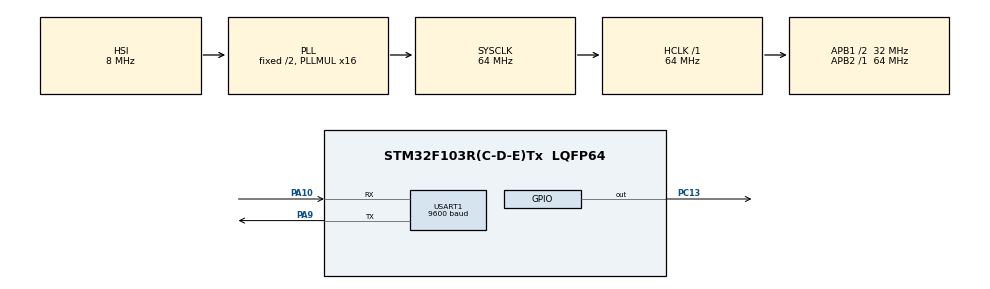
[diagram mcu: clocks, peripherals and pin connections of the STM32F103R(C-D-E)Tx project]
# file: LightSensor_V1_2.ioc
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Dma.Request0=USART1_RX
Dma.Request1=USART1_TX
Dma.USART1_RX.0.Direction=DMA_PERIPH_TO_MEMORY
Dma.USART1_RX.0.Instance=DMA1_Channel5
Dma.USART1_RX.0.MemDataAlignment=DMA_MDATAALIGN_BYTE
Dma.USART1_RX.0.MemInc=DMA_MINC_ENABLE
Dma.USART1_RX.0.Mode=DMA_NORMAL
Dma.USART1_RX.0.PeriphDataAlignment=DMA_PDATAALIGN_BYTE
Dma.USART1_RX.0.PeriphInc=DMA_PINC_DISABLE
Dma.USART1_RX.0.Priority=DMA_PRIORITY_LOW
Dma.USART1_TX.1.Direction=DMA_MEMORY_TO_PERIPH
Dma.USART1_TX.1.Instance=DMA1_Channel4
Dma.USART1_TX.1.MemDataAlignment=DMA_MDATAALIGN_BYTE
Dma.USART1_TX.1.MemInc=DMA_MINC_ENABLE
Dma.USART1_TX.1.Mode=DMA_NORMAL
Dma.USART1_TX.1.PeriphDataAlignment=DMA_PDATAALIGN_BYTE
Dma.USART1_TX.1.PeriphInc=DMA_PINC_DISABLE
Dma.USART1_TX.1.Priority=DMA_PRIORITY_LOW
FREERTOS.Tasks01=defaultTask,24,128,StartDefaultTask,Default,NULL,Dynamic,NULL,NULL
IWDG.Reload=3000
Mcu.Family=STM32F1
Mcu.Name=STM32F103R(C-D-E)Tx
Mcu.Package=LQFP64
NVIC.DMA1_Channel4_IRQn=true\:5\:0\:false\:false\:true\:true\:false\:true\:true
NVIC.DMA1_Channel5_IRQn=true\:5\:0\:false\:false\:true\:true\:false\:true\:true
NVIC.PriorityGroup=NVIC_PRIORITYGROUP_4
NVIC.TIM1_UP_IRQn=true\:15\:0\:false\:false\:true\:false\:false\:true\:true
NVIC.TimeBase=TIM1_UP_IRQn
NVIC.TimeBaseIP=TIM1
NVIC.USART1_IRQn=true\:5\:0\:false\:false\:true\:true\:true\:true\:true
PA10.Mode=Asynchronous
PA10.Signal=USART1_RX
PA13.Mode=Serial_Wire
PA13.Signal=SYS_JTMS-SWDIO
PA14.Mode=Serial_Wire
PA14.Signal=SYS_JTCK-SWCLK
PA9.Mode=Asynchronous
PA9.Signal=USART1_TX
PC13-TAMPER-RTC.GPIO_PuPd=GPIO_PULLUP
PC13-TAMPER-RTC.PinState=GPIO_PIN_SET
PC13-TAMPER-RTC.Signal=GPIO_Output
PC14-OSC32_IN.Mode=LSE-External-Oscillator
PC14-OSC32_IN.Signal=RCC_OSC32_IN
PC15-OSC32_OUT.Mode=LSE-External-Oscillator
PC15-OSC32_OUT.Signal=RCC_OSC32_OUT
ProjectManager.HeapSize=0x200
ProjectManager.StackSize=0x400
ProjectManager.TargetToolchain=MDK-ARM V5.32
RCC.AHBFreq_Value=64000000
RCC.APB1CLKDivider=RCC_HCLK_DIV2
RCC.APB1Freq_Value=32000000
RCC.APB1TimFreq_Value=64000000
RCC.APB2Freq_Value=64000000
RCC.APB2TimFreq_Value=64000000
RCC.HCLKFreq_Value=64000000
RCC.PLLMUL=RCC_PLL_MUL16
RCC.SYSCLKFreq_VALUE=64000000
RCC.SYSCLKSource=RCC_SYSCLKSOURCE_PLLCLK
RCC.USBFreq_Value=64000000
USART1.BaudRate=9600
USART1.VirtualMode=VM_ASYNC
VP_FREERTOS_VS_CMSIS_V2.Mode=CMSIS_V2
VP_IWDG_VS_IWDG.Mode=IWDG_Activate
VP_RTC_VS_RTC_Activate.Mode=RTC_Enabled
VP_RTC_VS_RTC_Calendar.Mode=RTC_Calendar
VP_SYS_VS_tim1.Mode=TIM1
board=custom

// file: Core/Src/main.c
/* USER CODE BEGIN Header */
/**
  ******************************************************************************
  * @file           : main.c
  * @brief          : Main program body
  ******************************************************************************
  * @attention
  *
  * Copyright (c) 2023 STMicroelectronics.
  * All rights reserved.
  *
  * This software is licensed under terms that can be found in the LICENSE file
  * in the root directory of this software component.
  * If no LICENSE file comes with this software, it is provided AS-IS.
  *
  ******************************************************************************
  */
/* USER CODE END Header */
#include "main.h"
#include "cmsis_os.h"
#include "dma.h"
#include "iwdg.h"
#include "rtc.h"
#include "usart.h"
#include "gpio.h"

/* USER CODE BEGIN Includes */
#include "stm32f1xx_it.h"
#include "user_TasksInit.h"
/* USER CODE END Includes */

void SystemClock_Config(void);
void MX_FREERTOS_Init(void);

int main(void)
{

  /* MCU Configuration--------------------------------------------------------*/

  /* Reset of all peripherals, Initializes the Flash interface and the Systick. */
  HAL_Init();

  /* Configure the system clock */
  SystemClock_Config();

  /* Initialize all configured peripherals */
  MX_GPIO_Init();
  MX_DMA_Init();
  //MX_IWDG_Init();
  MX_RTC_Init();
  MX_USART1_UART_Init();
  /* USER CODE BEGIN 2 */
	HAL_UART_Receive_DMA(&huart1,(uint8_t*)HardInt_receive_str_raw,120);
	__HAL_UART_ENABLE_IT(&huart1,UART_IT_IDLE);
  /* USER CODE END 2 */

  /* Init scheduler */
  osKernelInitialize();  /* Call init function for freertos objects (in freertos.c) */
  User_Tasks_Init();

  /* Start scheduler */
  osKernelStart();

  /* We should never get here as control is now taken by the scheduler */
  /* Infinite loop */
  while (1)
  {

  }
}

void SystemClock_Config(void)
{
  RCC_OscInitTypeDef RCC_OscInitStruct = {0};
  RCC_ClkInitTypeDef RCC_ClkInitStruct = {0};
  RCC_PeriphCLKInitTypeDef PeriphClkInit = {0};

  /** Initializes the RCC Oscillators according to the specified parameters
  * in the RCC_OscInitTypeDef structure.
  */
  RCC_OscInitStruct.OscillatorType = RCC_OSCILLATORTYPE_HSI|RCC_OSCILLATORTYPE_LSI;
  RCC_OscInitStruct.HSIState = RCC_HSI_ON;
  RCC_OscInitStruct.HSICalibrationValue = RCC_HSICALIBRATION_DEFAULT;
  RCC_OscInitStruct.LSIState = RCC_LSI_ON;
  RCC_OscInitStruct.PLL.PLLState = RCC_PLL_ON;
  RCC_OscInitStruct.PLL.PLLSource = RCC_PLLSOURCE_HSI_DIV2;
  RCC_OscInitStruct.PLL.PLLMUL = RCC_PLL_MUL16;
  if (HAL_RCC_OscConfig(&RCC_OscInitStruct) != HAL_OK)
  {
    Error_Handler();
  }

  /** Initializes the CPU, AHB and APB buses clocks
  */
  RCC_ClkInitStruct.ClockType = RCC_CLOCKTYPE_HCLK|RCC_CLOCKTYPE_SYSCLK
                              |RCC_CLOCKTYPE_PCLK1|RCC_CLOCKTYPE_PCLK2;
  RCC_ClkInitStruct.SYSCLKSource = RCC_SYSCLKSOURCE_PLLCLK;
  RCC_ClkInitStruct.AHBCLKDivider = RCC_SYSCLK_DIV1;
  RCC_ClkInitStruct.APB1CLKDivider = RCC_HCLK_DIV2;
  RCC_ClkInitStruct.APB2CLKDivider = RCC_HCLK_DIV1;

  if (HAL_RCC_ClockConfig(&RCC_ClkInitStruct, FLASH_LATENCY_2) != HAL_OK)
  {
    Error_Handler();
  }
  PeriphClkInit.PeriphClockSelection = RCC_PERIPHCLK_RTC;
  PeriphClkInit.RTCClockSelection = RCC_RTCCLKSOURCE_LSI;
  if (HAL_RCCEx_PeriphCLKConfig(&PeriphClkInit) != HAL_OK)
  {
    Error_Handler();
  }
}

void HAL_TIM_PeriodElapsedCallback(TIM_HandleTypeDef *htim)
{
  if (htim->Instance == TIM1) {
    HAL_IncTick();
  }
}

void Error_Handler(void)
{
  __disable_irq();
  while (1)
  {
  }
}

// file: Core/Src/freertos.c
/* USER CODE BEGIN Header */
/**
  ******************************************************************************
  * File Name          : freertos.c
  * Description        : Code for freertos applications
  ******************************************************************************
  * @attention
  *
  * Copyright (c) 2023 STMicroelectronics.
  * All rights reserved.
  *
  * This software is licensed under terms that can be found in the LICENSE file
  * in the root directory of this software component.
  * If no LICENSE file comes with this software, it is provided AS-IS.
  *
  ******************************************************************************
  */
/* USER CODE END Header */

#include "FreeRTOS.h"
#include "task.h"
#include "main.h"
#include "cmsis_os.h"

/* USER CODE BEGIN Includes */
#include "lcd_init.h"
#include "lcd.h"
/* USER CODE END Includes */

/* Definitions for defaultTask */
osThreadId_t defaultTaskHandle;
const osThreadAttr_t defaultTask_attributes = {
  .name = "defaultTask",
  .stack_size = 128 * 4,
  .priority = (osPriority_t) osPriorityNormal,
};

void StartDefaultTask(void *argument);

void MX_FREERTOS_Init(void); /* (MISRA C 2004 rule 8.1) */

void MX_FREERTOS_Init(void) {

  /* Create the thread(s) */
  /* creation of defaultTask */
  defaultTaskHandle = osThreadNew(StartDefaultTask, NULL, &defaultTask_attributes);

}

void StartDefaultTask(void *argument)
{
  /* USER CODE BEGIN StartDefaultTask */
	LCD_Init();
	LCD_Fill(0,0,LCD_W,LCD_H,BLACK);
	LCD_ShowString(0,50,"OK ",WHITE,BLACK,24,0);
  /* Infinite loop */
  for(;;)
  {
		HAL_GPIO_TogglePin(GPIOC,GPIO_PIN_13);
    osDelay(500);
  }
  /* USER CODE END StartDefaultTask */
}
